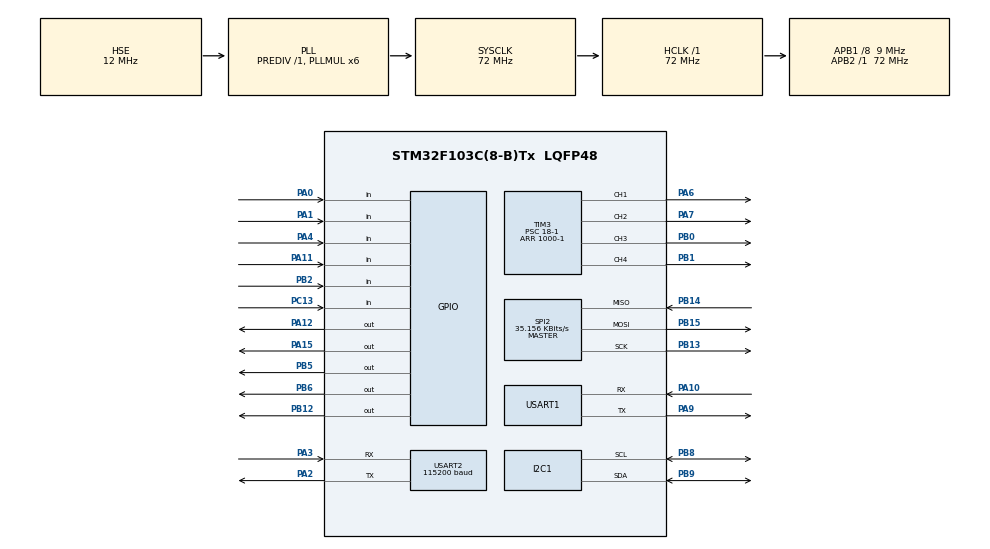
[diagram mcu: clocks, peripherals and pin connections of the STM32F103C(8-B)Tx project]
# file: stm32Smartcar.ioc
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Mcu.Family=STM32F1
Mcu.Name=STM32F103C(8-B)Tx
Mcu.Package=LQFP48
NVIC.PriorityGroup=NVIC_PRIORITYGROUP_4
NVIC.TIM4_IRQn=true\:0\:0\:false\:false\:true\:true\:true\:true
NVIC.USART1_IRQn=true\:7\:0\:true\:false\:true\:true\:true\:true
NVIC.USART2_IRQn=true\:7\:0\:true\:false\:true\:true\:true\:true
PA0-WKUP.Signal=GPIO_Input
PA1.Signal=GPIO_Input
PA10.Mode=Asynchronous
PA10.Signal=USART1_RX
PA11.Signal=GPIO_Input
PA12.Signal=GPIO_Output
PA15.Signal=GPIO_Output
PA2.Mode=Asynchronous
PA2.Signal=USART2_TX
PA3.Mode=Asynchronous
PA3.Signal=USART2_RX
PA4.Signal=GPIO_Input
PA6.Signal=S_TIM3_CH1
PA7.Signal=S_TIM3_CH2
PA9.Mode=Asynchronous
PA9.Signal=USART1_TX
PB0.Signal=S_TIM3_CH3
PB1.Signal=S_TIM3_CH4
PB12.Signal=GPIO_Output
PB13.Mode=Full_Duplex_Master
PB13.Signal=SPI2_SCK
PB14.Mode=Full_Duplex_Master
PB14.Signal=SPI2_MISO
PB15.Mode=Full_Duplex_Master
PB15.Signal=SPI2_MOSI
PB2.Signal=GPIO_Input
PB5.Signal=GPIO_Output
PB6.Signal=GPIO_Output
PB8.Mode=I2C
PB8.Signal=I2C1_SCL
PB9.Mode=I2C
PB9.Signal=I2C1_SDA
PC13-TAMPER-RTC.Signal=GPIO_Input
PC14-OSC32_IN.Mode=LSE-External-Oscillator
PC14-OSC32_IN.Signal=RCC_OSC32_IN
PC15-OSC32_OUT.Mode=LSE-External-Oscillator
PC15-OSC32_OUT.Signal=RCC_OSC32_OUT
PD0-OSC_IN.Mode=HSE-External-Oscillator
PD0-OSC_IN.Signal=RCC_OSC_IN
PD1-OSC_OUT.Mode=HSE-External-Oscillator
PD1-OSC_OUT.Signal=RCC_OSC_OUT
ProjectManager.HeapSize=0x200
ProjectManager.StackSize=0x400
ProjectManager.TargetToolchain=MDK-ARM V5.32
RCC.AHBFreq_Value=72000000
RCC.APB1CLKDivider=RCC_HCLK_DIV8
RCC.APB1Freq_Value=9000000
RCC.APB1TimFreq_Value=18000000
RCC.APB2Freq_Value=72000000
RCC.APB2TimFreq_Value=72000000
RCC.HCLKFreq_Value=72000000
RCC.HSE_VALUE=12000000
RCC.PLLMUL=RCC_PLL_MUL6
RCC.PLLSourceVirtual=RCC_PLLSOURCE_HSE
RCC.RTCClockSelection=RCC_RTCCLKSOURCE_LSE
RCC.SYSCLKFreq_VALUE=72000000
RCC.SYSCLKSource=RCC_SYSCLKSOURCE_PLLCLK
RCC.USBFreq_Value=72000000
RTC.Format=RTC_FORMAT_BIN
SH.S_TIM3_CH1.0=TIM3_CH1,PWM Generation1 CH1
SH.S_TIM3_CH2.0=TIM3_CH2,PWM Generation2 CH2
SH.S_TIM3_CH3.0=TIM3_CH3,PWM Generation3 CH3
SH.S_TIM3_CH4.0=TIM3_CH4,PWM Generation4 CH4
SPI2.BaudRatePrescaler=SPI_BAUDRATEPRESCALER_256
SPI2.CLKPolarity=SPI_POLARITY_HIGH
SPI2.CalculateBaudRate=35.156 KBits/s
SPI2.Direction=SPI_DIRECTION_2LINES
SPI2.FirstBit=SPI_FIRSTBIT_LSB
SPI2.Mode=SPI_MODE_MASTER
SPI2.VirtualType=VM_MASTER
TIM3.AutoReloadPreload=TIM_AUTORELOAD_PRELOAD_ENABLE
TIM3.Channel-PWM\ Generation1\ CH1=TIM_CHANNEL_1
TIM3.Channel-PWM\ Generation2\ CH2=TIM_CHANNEL_2
TIM3.Channel-PWM\ Generation3\ CH3=TIM_CHANNEL_3
TIM3.Channel-PWM\ Generation4\ CH4=TIM_CHANNEL_4
TIM3.Period=1000-1
TIM3.Prescaler=18-1
TIM4.AutoReloadPreload=TIM_AUTORELOAD_PRELOAD_ENABLE
TIM4.Period=500-1
TIM4.Prescaler=18000-1
USART1.VirtualMode=VM_ASYNC
USART2.BaudRate=115200
USART2.VirtualMode=VM_ASYNC
VP_RTC_No_RTC_Output.Mode=RTC_OUT_NO
VP_RTC_VS_RTC_Activate.Mode=RTC_Enabled
VP_SYS_VS_ND.Mode=No_Debug
VP_TIM3_VS_ClockSourceINT.Mode=Internal
VP_TIM4_VS_ClockSourceINT.Mode=Internal
board=custom

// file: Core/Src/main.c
/* USER CODE BEGIN Header */
/**
  ******************************************************************************
  * @file           : main.c
  * @brief          : Main program body
  ******************************************************************************
  * @attention
  *
  * Copyright (c) 2024 STMicroelectronics.
  * All rights reserved.
  *
  * This software is licensed under terms that can be found in the LICENSE file
  * in the root directory of this software component.
  * If no LICENSE file comes with this software, it is provided AS-IS.
  *
  ******************************************************************************
  */
/* USER CODE END Header */
#include "main.h"
#include "i2c.h"
#include "rtc.h"
#include "spi.h"
#include "tim.h"
#include "usart.h"
#include "gpio.h"

/* USER CODE BEGIN Includes */
#include "smartcar.h"
/* USER CODE END Includes */

void SystemClock_Config(void);

int main(void)
{

  /* MCU Configuration--------------------------------------------------------*/

  /* Reset of all peripherals, Initializes the Flash interface and the Systick. */
  HAL_Init();

  /* Configure the system clock */
  SystemClock_Config();

  /* Initialize all configured peripherals */
  MX_GPIO_Init();
  MX_USART1_UART_Init();
  MX_TIM3_Init();
  MX_SPI2_Init();
  MX_USART2_UART_Init();
  MX_TIM4_Init();
  MX_RTC_Init();
  MX_I2C1_Init();

  /* Infinite loop */
  /* USER CODE BEGIN WHILE */
  // led_on_off();
  //uart_test();
  // motor_test();
  // ps2_test();
  //bluetooth_test();
  //tm1637_test();
  //sht31_test();
  //__HAL_AFIO_REMAP_SWJ_NOJTAG(); // 禁用JTAG引脚
  //relay_test();
  //pid_test();
  while (1)
  {
	//key_scan(); // 按键要一直扫描
    /* USER CODE END WHILE */

  }
}

void SystemClock_Config(void)
{
  RCC_OscInitTypeDef RCC_OscInitStruct = {0};
  RCC_ClkInitTypeDef RCC_ClkInitStruct = {0};
  RCC_PeriphCLKInitTypeDef PeriphClkInit = {0};

  /** Initializes the RCC Oscillators according to the specified parameters
  * in the RCC_OscInitTypeDef structure.
  */
  RCC_OscInitStruct.OscillatorType = RCC_OSCILLATORTYPE_HSE|RCC_OSCILLATORTYPE_LSE;
  RCC_OscInitStruct.HSEState = RCC_HSE_ON;
  RCC_OscInitStruct.HSEPredivValue = RCC_HSE_PREDIV_DIV1;
  RCC_OscInitStruct.LSEState = RCC_LSE_ON;
  RCC_OscInitStruct.HSIState = RCC_HSI_ON;
  RCC_OscInitStruct.PLL.PLLState = RCC_PLL_ON;
  RCC_OscInitStruct.PLL.PLLSource = RCC_PLLSOURCE_HSE;
  RCC_OscInitStruct.PLL.PLLMUL = RCC_PLL_MUL6;
  if (HAL_RCC_OscConfig(&RCC_OscInitStruct) != HAL_OK)
  {
    Error_Handler();
  }

  /** Initializes the CPU, AHB and APB buses clocks
  */
  RCC_ClkInitStruct.ClockType = RCC_CLOCKTYPE_HCLK|RCC_CLOCKTYPE_SYSCLK
                              |RCC_CLOCKTYPE_PCLK1|RCC_CLOCKTYPE_PCLK2;
  RCC_ClkInitStruct.SYSCLKSource = RCC_SYSCLKSOURCE_PLLCLK;
  RCC_ClkInitStruct.AHBCLKDivider = RCC_SYSCLK_DIV1;
  RCC_ClkInitStruct.APB1CLKDivider = RCC_HCLK_DIV8;
  RCC_ClkInitStruct.APB2CLKDivider = RCC_HCLK_DIV1;

  if (HAL_RCC_ClockConfig(&RCC_ClkInitStruct, FLASH_LATENCY_2) != HAL_OK)
  {
    Error_Handler();
  }
  PeriphClkInit.PeriphClockSelection = RCC_PERIPHCLK_RTC;
  PeriphClkInit.RTCClockSelection = RCC_RTCCLKSOURCE_LSE;
  if (HAL_RCCEx_PeriphCLKConfig(&PeriphClkInit) != HAL_OK)
  {
    Error_Handler();
  }
}

void Error_Handler(void)
{
  __disable_irq();
  while (1)
  {
  }
}
